# MEC1322 register map
Vendor: Microchip Technology Inc.; Series: ARMCM4F; File version: 1.0
CPU: CM4 r1p0, little endian, MPU, FPU, 3 interrupt priority bits
Registers are 32-bit, read-write, reset 0x0 unless marked. A register's access mark holds for its fields unless they carry their own. Offsets are from the block's base; [hi:lo] are bit positions; {n}, {i} and the like mark numbered series.

## PCR — The Power, Clocks, and Resets (PCR) chapter identifies all the power supplies, clock sources, and reset inputs to the chip and defines all the derived power, clock, and reset signals.
Base 0x40080100
0x00 CHIP_SLP_EN — Chip Sleep Enable Register (CHIP_SLP_EN), MCHP Reserved
0x04 CHIP_CLK_REQ_STS ro — Chip Clock Required Status Registers (CHIP_CLK_REQ_STS), MCHP Reserved
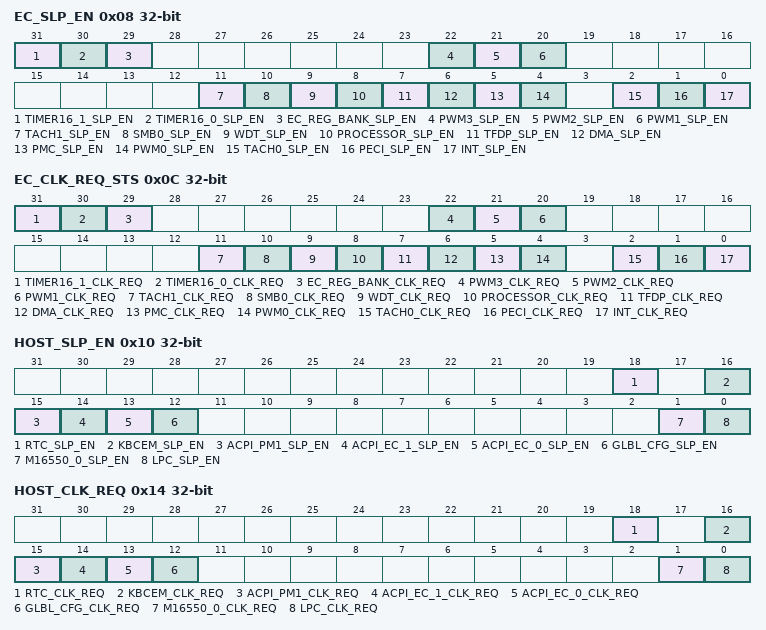
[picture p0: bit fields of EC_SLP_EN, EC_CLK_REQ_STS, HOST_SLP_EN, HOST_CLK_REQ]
0x08 EC_SLP_EN — EC Sleep Enable Register (EC_SLP_EN)
  [31] TIMER16_1_SLP_EN — TIMER16_1 Sleep Enable (TIMER16_1_SLP_EN)
  [30] TIMER16_0_SLP_EN — TIMER16_0 Sleep Enable (TIMER16_0_SLP_EN)
  [29] EC_REG_BANK_SLP_EN — EC_REG_BANK Sleep Enable (EC_REG_BANK_SLP_EN)
  [22] PWM3_SLP_EN — PWM3 Sleep Enable (PWM3_SLP_EN)
  [21] PWM2_SLP_EN — PWM2 Sleep Enable (PWM2_SLP_EN)
  [20] PWM1_SLP_EN — PWM1 Sleep Enable (PWM1_SLP_EN)
  [11] TACH1_SLP_EN — TACH1 Sleep Enable (TACH1_SLP_EN)
  [10] SMB0_SLP_EN — SMB0 Sleep Enable (SMB0_SLP_EN)
  [9] WDT_SLP_EN — WDT Sleep Enable (WDT_SLP_EN)
  [8] PROCESSOR_SLP_EN — PROCESSOR Sleep Enable (PROCESSOR_SLP_EN)
  [7] TFDP_SLP_EN — TFDP Sleep Enable (TFDP_SLP_EN)
  [6] DMA_SLP_EN — DMA Sleep Enable (DMA_SLP_EN)
  [5] PMC_SLP_EN — PMC Sleep Enable (PMC_SLP_EN)
  [4] PWM0_SLP_EN — PWM0 Sleep Enable (PWM0_SLP_EN)
  [2] TACH0_SLP_EN — TACH0 Sleep Enable (TACH0_SLP_EN)
  [1] PECI_SLP_EN — PECI Sleep Enable (PECI_SLP_EN)
  [0] INT_SLP_EN — INT Sleep Enable (INT_SLP_EN)
0x0C EC_CLK_REQ_STS — EC Clock Required Status Registers (EC_CLK_REQ_STS)
  [31] TIMER16_1_CLK_REQ ro — TIMER16_1 Clock Required (TIMER16_1_CLK_REQ)
  [30] TIMER16_0_CLK_REQ ro — TIMER16_0 Clock Required (TIMER16_0_CLK_REQ)
  [29] EC_REG_BANK_CLK_REQ ro — EC_REG_BANK Clock Required (EC_REG_BANK_CLK_REQ)
  [22] PWM3_CLK_REQ ro — PWM3 Clock Required (PWM3_CLK_REQ)
  [21] PWM2_CLK_REQ ro — PWM2 Clock Required (PWM2_CLK_REQ)
  [20] PWM1_CLK_REQ ro — PWM1 Clock Required (PWM1_CLK_REQ)
  [11] TACH1_CLK_REQ ro — TACH1 Clock Required (TACH1_CLK_REQ)
  [10] SMB0_CLK_REQ ro — SMB0 Clock Required (SMB0_CLK_REQ)
  [9] WDT_CLK_REQ ro — WDT Clock Required (WDT_CLK_REQ)
  [8] PROCESSOR_CLK_REQ ro — PROCESSOR Clock Required (PROCESSOR_CLK_REQ)
  [7] TFDP_CLK_REQ ro — TFDP Clock Required (TFDP_CLK_REQ)
  [6] DMA_CLK_REQ ro — DMA Clock Required (DMA_CLK_REQ)
  [5] PMC_CLK_REQ ro — PMC Clock Required (PMC_CLK_REQ)
  [4] PWM0_CLK_REQ ro — PWM0 Clock Required (PWM0_CLK_REQ)
  [2] TACH0_CLK_REQ ro — TACH0 Clock Required (TACH0_CLK_REQ)
  [1] PECI_CLK_REQ — PECI Clock Required (PECI_CLK_REQ)
  [0] INT_CLK_REQ ro — INT Clock Required (INT_CLK_REQ)
0x10 HOST_SLP_EN — Host Sleep Enable Register (HOST_SLP_EN)
  [18] RTC_SLP_EN — RTC Sleep Enable (RTC_SLP_EN)
  [16] KBCEM_SLP_EN — 8042EM Sleep Enable (8042EM_SLP_EN)
  [15] ACPI_PM1_SLP_EN — ACPI PM1 Sleep Enable (ACPI_PM1_SLP_EN)
  [14] ACPI_EC_1_SLP_EN — ACPI EC 1 Sleep Enable (ACPI_EC_1_SLP_EN)
  [13] ACPI_EC_0_SLP_EN — ACPI EC 0 Sleep Enable (ACPI_EC_0_SLP_EN)
  [12] GLBL_CFG_SLP_EN — GLBL_CFG (GLBL_CFG_SLP_EN)
  [1] M16550_0_SLP_EN — UART 0 Sleep Enable (M16550_0_SLP_EN)
  [0] LPC_SLP_EN — LPC Sleep Enable (LPC_SLP_EN)
0x14 HOST_CLK_REQ — Host Clock Required Status Registers (HOST_CLK_REQ)
  [18] RTC_CLK_REQ ro — RTC Clock Required (RTC_CLK_REQ)
  [16] KBCEM_CLK_REQ ro — 8042EM Clock Required (8042EM_CLK_REQ)
  [15] ACPI_PM1_CLK_REQ ro — ACPI PM1 Clock Required (ACPI_PM1_CLK_REQ)
  [14] ACPI_EC_1_CLK_REQ ro — ACPI EC 1 Clock Required (ACPI_EC_1_CLK_REQ)
  [13] ACPI_EC_0_CLK_REQ ro — ACPI EC 0 Clock Required (ACPI_EC_0_CLK_REQ)
  [12] GLBL_CFG_CLK_REQ ro — GLBL_CFG Clock Required (GLBL_CFG_CLK_REQ)
  [1] M16550_0_CLK_REQ ro — UART 0 Clock Required (M16550_0_CLK_REQ)
  [0] LPC_CLK_REQ ro — LPC Clock Required (LPC_CLK_REQ)
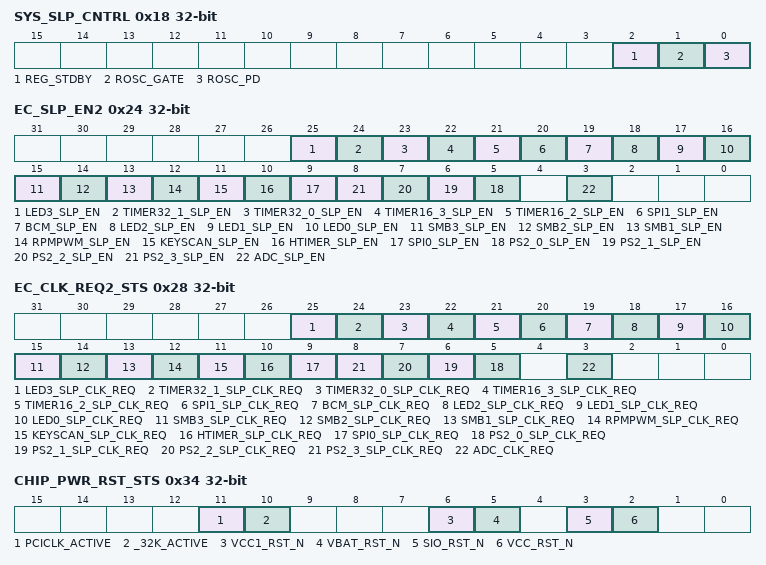
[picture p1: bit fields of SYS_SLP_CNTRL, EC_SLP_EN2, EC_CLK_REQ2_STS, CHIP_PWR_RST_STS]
0x18 SYS_SLP_CNTRL — System Sleep Control Register (SYS_SLP_CNTRL)
  [2] REG_STDBY — Core regulator standby (REG_STDBY)
  [1] ROSC_GATE — Ring oscillator output gate (ROSC_GATE)
  [0] ROSC_PD — Ring oscillator power down (ROSC_PD)
0x20 PROC_CLK_CNTRL — Processor Clock Control Register (PROC_CLK_CNTRL) [7:0] Processor Clock Divide Value (PROC_DIV). 0: Clock off (suicide for the processor to do this). 1: divide 48 MHz Ring Oscillator by 1. 4: divide 48 MHz Ring Oscillator by 4. 16: divide 48 MHz Ring Oscillator by 16. 48: divide 48 MHz Ring Oscillator by 48. No other values are supported
0x24 EC_SLP_EN2 — EC Sleep Enable 2 Register (EC_SLP_EN2)
  [25] LED3_SLP_EN — LED3 Sleep Enable (LED3_SLP_EN)
  [24] TIMER32_1_SLP_EN — TIMER32_1 Sleep Enable (TIMER32_1_SLP_EN)
  [23] TIMER32_0_SLP_EN — TIMER32_0 Sleep Enable (TIMER32_0_SLP_EN)
  [22] TIMER16_3_SLP_EN — TIMER16_3 Sleep Enable (TIMER16_3_SLP_EN)
  [21] TIMER16_2_SLP_EN — TIMER16_2_Sleep Enable (TIMER16_2_SLP_EN)
  [20] SPI1_SLP_EN — SPI1 Sleep Enable (SPI1_SLP_EN)
  [19] BCM_SLP_EN — BCM Sleep Enable (BCM_SLP_EN)
  [18] LED2_SLP_EN — LED2 Sleep Enable (LED2_SLP_EN)
  [17] LED1_SLP_EN — LED1 Sleep Enable (LED1_SLP_EN)
  [16] LED0_SLP_EN — LED0 Sleep Enable (LED0_SLP_EN)
  [15] SMB3_SLP_EN — SMB3 Sleep Enable (SMB3_SLP_EN)
  [14] SMB2_SLP_EN — SMB2 Sleep Enable (SMB2_SLP_EN)
  [13] SMB1_SLP_EN — SMB1 Sleep Enable (SMB1_SLP_EN)
  [12] RPMPWM_SLP_EN — RPM-PWM Sleep Enable (RPMPWM_SLP_EN)
  [11] KEYSCAN_SLP_EN — KEYSCAN Sleep Enable (KEYSCAN_SLP_EN)
  [10] HTIMER_SLP_EN — HTIMER Sleep Enable (HTIMER_SLP_EN)
  [9] SPI0_SLP_EN — SPI0 Sleep Enable (SPI0_SLP_EN)
  [n+5] PS2_{n}_SLP_EN (n=0..3) — PS2_{n} Sleep Enable (PS2_{n}_SLP_EN)
  [3] ADC_SLP_EN — ADC Sleep Enable (ADC_SLP_EN)
0x28 EC_CLK_REQ2_STS — EC Clock Required 2 Status Register (EC_CLK_REQ2_STS)
  [25] LED3_SLP_CLK_REQ ro — LED3 Clock Required (LED3_SLP_CLK_REQ)
  [24] TIMER32_1_SLP_CLK_REQ ro — TIMER32_1 Clock Required (TIMER32_1_SLP_CLK_REQ)
  [23] TIMER32_0_SLP_CLK_REQ ro — TIMER32_0 Clock Required (TIMER32_0_SLP_CLK_REQ)
  [22] TIMER16_3_SLP_CLK_REQ ro — TIMER16_3 Clock Required (TIMER16_3_SLP_CLK_REQ)
  [21] TIMER16_2_SLP_CLK_REQ ro — TIMER16_2_Clock Required (TIMER16_2_SLP_CLK_REQ)
  [20] SPI1_SLP_CLK_REQ ro — SPI1 Clock Required (SPI1_SLP_CLK_REQ)
  [19] BCM_SLP_CLK_REQ ro — BCM Clock Required (BCM_SLP_CLK_REQ)
  [18] LED2_SLP_CLK_REQ ro — LED2 Clock Required (LED2_SLP_CLK_REQ)
  [17] LED1_SLP_CLK_REQ ro — LED1 Clock Required (LED1_SLP_CLK_REQ)
  [16] LED0_SLP_CLK_REQ ro — LED0 Clock Required (LED0_SLP_CLK_REQ)
  [15] SMB3_SLP_CLK_REQ ro — SMB3 Clock Required (SMB3_SLP_CLK_REQ)
  [14] SMB2_SLP_CLK_REQ ro — SMB2 Clock Required (SMB2_SLP_CLK_REQ)
  [13] SMB1_SLP_CLK_REQ ro — SMB1 Clock Required (SMB1_SLP_CLK_REQ)
  [12] RPMPWM_SLP_CLK_REQ ro — RPM-PWM Clock Required (RPMPWM_SLP_CLK_REQ)
  [11] KEYSCAN_SLP_CLK_REQ ro — KEYSCAN Clock Required (KEYSCAN_SLP_CLK_REQ)
  [10] HTIMER_SLP_CLK_REQ ro — HTIMER Clock Required (HTIMER_SLP_CLK_REQ)
  [9] SPI0_SLP_CLK_REQ ro — SPI0 Clock Required (SPI0_SLP_CLK_REQ)
  [n+5] PS2_{n}_SLP_CLK_REQ ro (n=0..3) — PS2_{n} Clock Required (PS2_{n}_SLP_CLK_REQ)
  [3] ADC_CLK_REQ ro — ADC Clock Required (ADC_CLK_REQ)
0x2C SLOW_CLK_CNTRL reset 0x1E0 — Slow Clock Control Register (SLOW_CLK_CNTRL) Slow Clock (100 kHz) Divide Value (slow_div) Configures the 100kHz_Clk. 0: Clock off n: divide by n. Note: The default setting is for 100 kHz.
0x30 CHIP_OSC_ID — Oscillator ID Register (CHIP_OSC_ID)
  [8] OSC_LOCK — OSC_LOCK (OSC_LOCK)
0x34 CHIP_PWR_RST_STS — PCR chip sub-system power reset status (CHIP_PWR_RST_STS)
  [11] PCICLK_ACTIVE ro — PCICLK_ACTIVE (PCICLK_ACTIVE)
  [10] _32K_ACTIVE ro — 32K_ACTIVE (32K_ACTIVE)
  [6] VCC1_RST_N — VCC1 reset status (VCC1_RST_N) Indicates the status of VCC1_RESET.(R/WC). 0 = No reset occurred since the last time this bit was cleared. 1 = A reset occurred.
  [5] VBAT_RST_N — VBAT reset status (VBAT_RST_N) 0 = No reset occurred while VCC1 was off or since the last time this bit was cleared. 1 = A reset occurred.(R/WC)
  [3] SIO_RST_N ro — SIO_Reset Status (SIO_RST_N) Indicates the status of nSIO_RESET. 0 = reset active. 1 = reset not active.
  [2] VCC_RST_N ro — VCC Reset Status (VCC_RST_N) Indicates the status of PWRGD. 0 = reset active (PWRGD not asserted). 1 = reset not active (PWRGD asserted).
0x38 CHIP_RST_EN — Chip Reset Enable Register (CHIP_RST_EN) MCHP Reserved
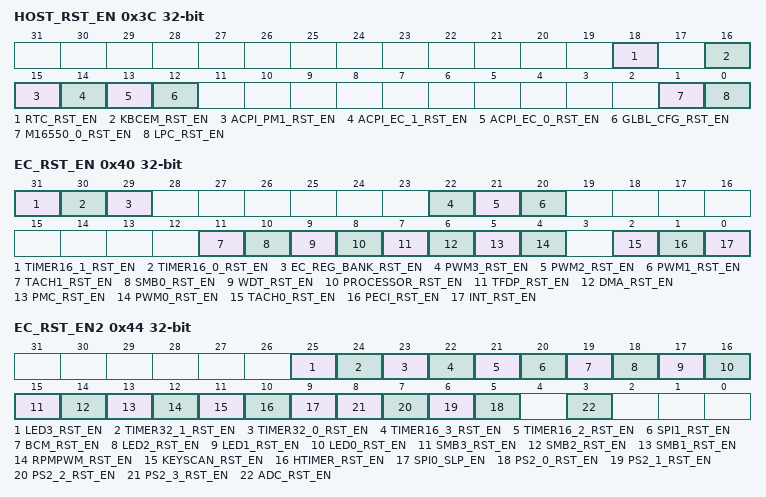
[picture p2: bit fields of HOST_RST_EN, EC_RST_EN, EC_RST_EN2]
0x3C HOST_RST_EN — Host Reset Enable Register (HOST_RST_EN) 0: block will not be reset on sleep. 1: block will be reset on sleep.
  [18] RTC_RST_EN — RTC Reset Enable (RTC_RST_EN)
  [16] KBCEM_RST_EN — 8042EM Reset Enable (8042EM_RST_EN)
  [15] ACPI_PM1_RST_EN — ACPI PM1 Reset Enable (ACPI_PM1_RST_EN)
  [14] ACPI_EC_1_RST_EN — ACPI EC 1 Reset Enable (ACPI_EC_1_RST_EN)
  [13] ACPI_EC_0_RST_EN — ACPI EC 0 Reset Enable (ACPI_EC_0_RST_EN)
  [12] GLBL_CFG_RST_EN — GLBL_CFG Reset Enable (GLBL_CFG_RST_EN)
  [1] M16550_0_RST_EN — UART 0 Reset Enable (M16550_0_RST_EN)
  [0] LPC_RST_EN — LPC Reset Enable (LPC_RST_EN)
0x40 EC_RST_EN — EC Reset Enable Register (EC_RST_EN) 0: block will not be reset on sleep. 1: block will be reset on sleep.
  [31] TIMER16_1_RST_EN — TIMER16_1 Reset Enable (TIMER16_1_RST_EN)
  [30] TIMER16_0_RST_EN — TIMER16_0 Reset Enable (TIMER16_0_RST_EN)
  [29] EC_REG_BANK_RST_EN — EC_REG_BANK Reset Enable (EC_REG_BANK_RST_EN)
  [22] PWM3_RST_EN — PWM3 Reset Enable (PWM3_RST_EN)
  [21] PWM2_RST_EN — PWM2 Reset Enable (PWM2_RST_EN)
  [20] PWM1_RST_EN — PWM1 Reset Enable (PWM1_RST_EN)
  [11] TACH1_RST_EN — TACH1 Reset Enable (TACH1_RST_EN)
  [10] SMB0_RST_EN — SMB0 Reset Enable (SMB0_RST_EN)
  [9] WDT_RST_EN — WDT Reset Enable (WDT_RST_EN)
  [8] PROCESSOR_RST_EN — PROCESSOR Sleep Enable (PROCESSOR_RST_EN)
  [7] TFDP_RST_EN — TFDP Reset Enable (TFDP_RST_EN)
  [6] DMA_RST_EN — DMA Reset Enable (DMA_RST_EN)
  [5] PMC_RST_EN — PMC Reset Enable (PMC_RST_EN)
  [4] PWM0_RST_EN — PWM0 Reset Enable (PWM0_RST_EN)
  [2] TACH0_RST_EN — TACH0 Reset Enable (TACH0_RST_EN)
  [1] PECI_RST_EN — PECI Reset Enable (PECI_RST_EN)
  [0] INT_RST_EN — INT Reset Enable (INT_RST_EN)
0x44 EC_RST_EN2 — EC Reset Enable 2 Register (EC_RST_EN2) 0: block will not be reset on sleep. 1: block will be reset on sleep.
  [25] LED3_RST_EN — LED3 Reset Enable (LED3_RST_EN)
  [24] TIMER32_1_RST_EN — TIMER32_1 Reset Enable (TIMER32_1_RST_EN)
  [23] TIMER32_0_RST_EN — TIMER32_0 Reset Enable (TIMER32_0_RST_EN)
  [22] TIMER16_3_RST_EN — TIMER16_3 Reset Enable (TIMER16_3_RST_EN)
  [21] TIMER16_2_RST_EN — TIMER16_2_Reset Enable (TIMER16_2_RST_EN)
  [20] SPI1_RST_EN — SPI1 Reset Enable (SPI1_RST_EN)
  [19] BCM_RST_EN — BCM Reset Enable (BCM_RST_EN)
  [18] LED2_RST_EN — LED2 Reset Enable (LED2_RST_EN)
  [17] LED1_RST_EN — LED1 Reset Enable (LED1_RST_EN)
  [16] LED0_RST_EN — LED0 Reset Enable (LED0_RST_EN)
  [15] SMB3_RST_EN — SMB3 Reset Enable (SMB3_RST_EN)
  [14] SMB2_RST_EN — SMB2 Reset Enable (SMB2_RST_EN)
  [13] SMB1_RST_EN — SMB1 Reset Enable (SMB1_RST_EN)
  [12] RPMPWM_RST_EN — RPM-PWM Reset Enable (RPMPWM_RST_EN)
  [11] KEYSCAN_RST_EN — KEYSCAN Reset Enable (KEYSCAN_RST_EN)
  [10] HTIMER_RST_EN — HTIMER Reset Enable (HTIMER_RST_EN)
  [9] SPI0_SLP_EN — SPI0 Reset Enable (SPI0_SLP_EN)
  [n+5] PS2_{n}_RST_EN (n=0..3) — PS2_{n} Reset Enable (PS2_{n}_RST_EN)
  [3] ADC_RST_EN — ADC Reset Enable (ADC_RST_EN)
0x48 PWR_RST_CTRL reset 0x1 — Power Reset Control (PWR_RST_CTRL) Register
  [0] IRESET_OUT — iRESET_OUT (IRESET_OUT)
